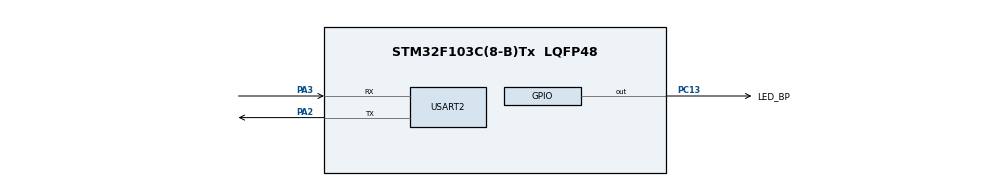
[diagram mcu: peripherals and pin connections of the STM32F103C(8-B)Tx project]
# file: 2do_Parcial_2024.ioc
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FREERTOS.Tasks01=defaultTask,24,128,StartDefaultTask,Default,NULL,Dynamic,NULL,NULL
FREERTOS.configTOTAL_HEAP_SIZE=8000
FREERTOS.configUSE_NEWLIB_REENTRANT=1
FREERTOS.configUSE_TICKLESS_IDLE=1
Mcu.Family=STM32F1
Mcu.Name=STM32F103C(8-B)Tx
Mcu.Package=LQFP48
NVIC.PriorityGroup=NVIC_PRIORITYGROUP_4
NVIC.TIM1_UP_IRQn=true\:15\:0\:false\:false\:true\:false\:false\:true\:true
NVIC.TimeBase=TIM1_UP_IRQn
NVIC.TimeBaseIP=TIM1
NVIC.USART2_IRQn=true\:5\:0\:false\:false\:true\:true\:true\:true\:true
PA13.Mode=Serial_Wire
PA13.Signal=SYS_JTMS-SWDIO
PA14.Mode=Serial_Wire
PA14.Signal=SYS_JTCK-SWCLK
PA2.Mode=Asynchronous
PA2.Signal=USART2_TX
PA3.Mode=Asynchronous
PA3.Signal=USART2_RX
PC13-TAMPER-RTC.GPIO_Label=LED_BP
PC13-TAMPER-RTC.Signal=GPIO_Output
PC14-OSC32_IN.Mode=LSE-External-Oscillator
PC14-OSC32_IN.Signal=RCC_OSC32_IN
PC15-OSC32_OUT.Mode=LSE-External-Oscillator
PC15-OSC32_OUT.Signal=RCC_OSC32_OUT
PD0-OSC_IN.Mode=HSE-External-Oscillator
PD0-OSC_IN.Signal=RCC_OSC_IN
PD1-OSC_OUT.Mode=HSE-External-Oscillator
PD1-OSC_OUT.Signal=RCC_OSC_OUT
ProjectManager.HeapSize=0x200
ProjectManager.StackSize=0x400
ProjectManager.TargetToolchain=STM32CubeIDE
RCC.APB1Freq_Value=8000000
RCC.APB2Freq_Value=8000000
USART2.VirtualMode=VM_ASYNC
VP_FREERTOS_VS_CMSIS_V2.Mode=CMSIS_V2
VP_SYS_VS_tim1.Mode=TIM1
board=custom

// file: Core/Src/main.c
/* USER CODE BEGIN Header */
/**
 ******************************************************************************
 * @file           : main.c
 * @brief          : Main program body
 ******************************************************************************
 * @attention
 *
 * Copyright (c) 2025 STMicroelectronics.
 * All rights reserved.
 *
 * This software is licensed under terms that can be found in the LICENSE file
 * in the root directory of this software component.
 * If no LICENSE file comes with this software, it is provided AS-IS.
 *
 ******************************************************************************
 */
/* USER CODE END Header */
#include "main.h"
#include "cmsis_os.h"

/* USER CODE BEGIN Includes */
#include "FreeRTOS.h"
#include "task.h"
#include "semphr.h"
#include "queue.h"
#include "string.h"
#include <stdio.h>

/* USER CODE END Includes */

/* USER CODE BEGIN PTD */

typedef struct TASK_DATA {
	uint16_t SI_PIN;
	uint16_t SF_PIN;
	uint16_t BARRERA_PIN;
	uint16_t TIPO;
	xSemaphoreHandle sem_SI;
	xSemaphoreHandle sem_SF;
}TASK_DATA_T;
/* USER CODE END PTD */

/* USER CODE BEGIN PD */
#define S1_PIN (0) /* Pin sensor entrada barrera entrada */
#define S2_PIN (1) /* Pin sensor salida barrera entrada */
#define S3_PIN (2) /* Pin sensor entrada barrera salida */
#define S4_PIN (3) /* Pin sensor salida barrera salida */
#define O1_PIN (4) /* Pin para control barrera entrada */
#define O2_PIN (5) /* Pin para control barrera salida */
#define O3_PIN (6) /* Pin semáforo verde */
#define O4_PIN (7) /* Pin semáforo rojo */

#define QUEUE_LEN (5)

#define ENTRADA 0
#define SALIDA 1
#define O5_MINUTOS 2
#define TIEMPO 60000
#define ESPERA 300000
/* USER CODE END PD */

UART_HandleTypeDef huart2;

/* Definitions for defaultTask */
osThreadId_t defaultTaskHandle;
const osThreadAttr_t defaultTask_attributes = {
		.name = "defaultTask",
		.stack_size = 128 * 4,
		.priority = (osPriority_t) osPriorityNormal,
};
/* USER CODE BEGIN PV */

uint32_t leer_nro_autos(void){return 0;}; /* Thread-safe: no */
uint32_t max_autos(void){return 0;}; /* Thread-safe: si */
void decrementar_autos(void){}; /* Thread-safe: no */
void incrementar_autos(void){}; /* Thread-safe: no */
uint32_t ingreso_permitido(void){return 0;}; /* Thread-safe: si */

/* Escribe 0 o 1 en el pin */
void gpio_write(uint16_t pin, uint32_t valor){};
/* Devuelve 0 o 1 en función del estado del pin */
uint32_t gpio_read(uint16_t pin){return 0;};
/* Envía el mensaje str de len bytes utilizando interrupciones de UART */
uint32_t uart_send(uint8_t *str, uint16_t len);
/* Prototipo del callback del handler de interrupciones de GPIO */
void HAL_GPIO_EXTI_Callback(uint16_t pin);

static TASK_DATA_T entrada, salida;

static xSemaphoreHandle mutex_colector, sem_cont;

// Para la Queue
static QueueHandle_t queue_uart;
static uint8_t dato_cola;

/* USER CODE END PV */

void SystemClock_Config(void);
static void MX_GPIO_Init(void);
static void MX_USART2_UART_Init(void);
void StartDefaultTask(void *argument);

/* USER CODE BEGIN PFP */

static void initTasksData(void)
{
	entrada.SI_PIN = S1_PIN;
	entrada.SF_PIN = S2_PIN;
	entrada.BARRERA_PIN = O1_PIN;
	entrada.sem_SI = xSemaphoreCreateBinary();
	entrada.sem_SF = xSemaphoreCreateBinary();
	entrada.TIPO = ENTRADA;

	salida.SI_PIN = S3_PIN;
	salida.SF_PIN = S4_PIN;
	salida.BARRERA_PIN = O2_PIN;
	salida.sem_SI = xSemaphoreCreateBinary();
	salida.sem_SF = xSemaphoreCreateBinary();
	salida.TIPO = SALIDA;

	gpio_write(O1_PIN,0);
	gpio_write(O2_PIN,0);
	gpio_write(O3_PIN,0);
	gpio_write(O4_PIN,0);

	mutex_colector = xSemaphoreCreateMutex();
	sem_cont = xSemaphoreCreateBinary();
}

void taskBarrera (void *a){
	TASK_DATA_T *p;
	p = (TASK_DATA_T*)a;

	uint32_t cont = 0; // Para contar el tiempo de barrera
	uint8_t item;

	while(1)
	{
		if(leer_nro_autos() < max_autos()) // Hay lugares disponibles, prendo las luces
		{
			gpio_write(O3_PIN,1);
			gpio_write(O4_PIN,0);
		}
		else if(leer_nro_autos() == max_autos() ||ingreso_permitido() == 0 )
		{
			gpio_write(O3_PIN,0);
			gpio_write(O4_PIN,1);
		}
		xSemaphoreTake(p->sem_SI,portMAX_DELAY); // Tomo semafoto del sensor de ENTRADA
		if (leer_nro_autos() == max_autos()  || ingreso_permitido() == 0) // Si esta lleno o ingreso permitido es 0 no permito la entrada de vehiculos
		{
			if(p->TIPO == SALIDA) // Es del tipo salida
			{
				gpio_write(p->BARRERA_PIN, 1); // abro la barrera de SALIDA
				while (xSemaphoreTake(p->sem_SF,0) == pdFALSE && cont < TIEMPO) // Mientras no se active S2 y el contador sea menor a 1 min
				{
					cont++; // Contador suma
					vTaskDelay(1); // Espera 1ms
				}
				// Salio del While por dos razones: por TIEMPO o se activo S2

				if (cont < TIEMPO ) // Paso el auto porque se activo el semaforo
				{
					xSemaphoreGive(sem_cont); //Reseteo contador de 5 min
					// ~~~~~~~~~~~~~~~~~~~~~~~~~~~~~~~~~
					xSemaphoreTake(mutex_colector,portMAX_DELAY);
					decrementar_autos();
					xSemaphoreGive(mutex_colector);
					// ~~~~~~~~~~~~~~~~~~~~~~~~~~~~~~~~~

					item = p->TIPO;
					xQueueSend(queue_uart, &item, 0); // Mando el mensaje a la UART
				}
			}

		}
		else // Condiciones normales
		{
			gpio_write(p->BARRERA_PIN, 1);
			while (xSemaphoreTake(p->sem_SF,0) == pdFALSE && cont < TIEMPO) // Mientras no se active S2 y el contador sea menor a 1 min
			{
				cont++; // Contador suma
				vTaskDelay(1); //Espera 1ms
			}
			// Salio del While por dos razones: por TIEMPO o se activo S2

			if (cont < TIEMPO ) // Paso el auto porque se activo el semaforo
			{

				if(p->TIPO == ENTRADA){

					xSemaphoreGive(sem_cont); //Reseteo contador de 5 min
					// ~~~~~~~~~~~~~~~~~~~~~~~~~~~~~~~~~
					xSemaphoreTake(mutex_colector,portMAX_DELAY);
					incrementar_autos();
					xSemaphoreGive(mutex_colector);
					// ~~~~~~~~~~~~~~~~~~~~~~~~~~~~~~~~~

				}else if ( p->TIPO == SALIDA)
				{
					xSemaphoreGive(sem_cont); //Reseteo contador de 5 min
					// ~~~~~~~~~~~~~~~~~~~~~~~~~~~~~~~~~
					xSemaphoreTake(mutex_colector,portMAX_DELAY);
					decrementar_autos();
					xSemaphoreGive(mutex_colector);
					// ~~~~~~~~~~~~~~~~~~~~~~~~~~~~~~~~~
				}
				item = p->TIPO;
				xQueueSend(queue_uart, &item, 0); // Mando el mensaje a la UART
			}

		}

		gpio_write(p->BARRERA_PIN, 0); // Cierro la barrera
		cont = 0; // Reseteo el contador
	}
}

void Task_uart(void *p){

	uint8_t item;
	uint8_t buff[128];

	while(1){
		xQueueReceive(queue_uart, &item, portMAX_DELAY);

		if(item == ENTRADA)
		{
			snprintf((char*)buff,128," “Barrera de ENTRADA: %d-%d\r\n”",(int)leer_nro_autos(),(int)max_autos());
		}
		if(item == SALIDA)
		{
			snprintf((char*)buff,128," “Barrera de SALIDA: %d-%d\r\n”",(int)leer_nro_autos(),(int)max_autos());
		}
		if(item == O5_MINUTOS)
		{
			snprintf((char*)buff,128," “ESTADO: %d-%d\r\n”",(int)leer_nro_autos(),(int)max_autos());
		}

		HAL_UART_Transmit(&huart2, buff, (uint16_t)strlen((char *)buff), 100);
	}

}

void Task_cont (void *a) // Esta tarea va a contar el tiempo desde que no se abrio las barreras
{
	uint8_t item;
	uint32_t cont = 0;

	while(1)
	{
		while(xSemaphoreTake(sem_cont,0) == pdFALSE && cont < ESPERA) // Espero que se termine el tiempo o Pase un auto por las BARRERAS
		{
			cont++;
			vTaskDelay(1);
		}

		if ( cont  > ESPERA ) // 5 minutos desde que no hubo autos en las barreras
		{
			item = O5_MINUTOS;
			xQueueSend(queue_uart, &item, 0);
		}

		cont = 0;
	}

}

/* USER CODE END PFP */

int main(void)
{

	/* MCU Configuration--------------------------------------------------------*/

	/* Reset of all peripherals, Initializes the Flash interface and the Systick. */
	HAL_Init();

	/* Configure the system clock */
	SystemClock_Config();

	/* Initialize all configured peripherals */
	MX_GPIO_Init();
	MX_USART2_UART_Init();
	/* USER CODE BEGIN 2 */
	initTasksData();
	/* USER CODE END 2 */

	/* Init scheduler */
	osKernelInitialize();

	/* USER CODE BEGIN RTOS_QUEUES */
	/* add queues, ... */
	queue_uart = xQueueCreate(QUEUE_LEN, sizeof(dato_cola));
	/* USER CODE END RTOS_QUEUES */

	/* Create the thread(s) */
	/* creation of defaultTask */
	defaultTaskHandle = osThreadNew(StartDefaultTask, NULL, &defaultTask_attributes);

	/* USER CODE BEGIN RTOS_THREADS */
	/* add threads, ... */
	xTaskCreate(taskBarrera, (const char *)"TaskBarrera_Entrada", configMINIMAL_STACK_SIZE, &entrada, osPriorityNormal, NULL);
	xTaskCreate(taskBarrera, (const char *)"TaskBarrera_Salida", configMINIMAL_STACK_SIZE, &salida, osPriorityNormal, NULL);
	xTaskCreate(Task_uart, (const char *)"task_uart", configMINIMAL_STACK_SIZE, NULL, osPriorityNormal, NULL);
	xTaskCreate(Task_cont, (const char *)"task_cont", configMINIMAL_STACK_SIZE, NULL, osPriorityNormal, NULL);

	/* USER CODE END RTOS_THREADS */

	/* Start scheduler */
	osKernelStart();

	/* We should never get here as control is now taken by the scheduler */

	/* Infinite loop */
	while (1)
	{

	}
}

void SystemClock_Config(void)
{
	RCC_OscInitTypeDef RCC_OscInitStruct = {0};
	RCC_ClkInitTypeDef RCC_ClkInitStruct = {0};

	/** Initializes the RCC Oscillators according to the specified parameters
	 * in the RCC_OscInitTypeDef structure.
	 */
	RCC_OscInitStruct.OscillatorType = RCC_OSCILLATORTYPE_HSI;
	RCC_OscInitStruct.HSIState = RCC_HSI_ON;
	RCC_OscInitStruct.HSICalibrationValue = RCC_HSICALIBRATION_DEFAULT;
	RCC_OscInitStruct.PLL.PLLState = RCC_PLL_NONE;
	if (HAL_RCC_OscConfig(&RCC_OscInitStruct) != HAL_OK)
	{
		Error_Handler();
	}

	/** Initializes the CPU, AHB and APB buses clocks
	 */
	RCC_ClkInitStruct.ClockType = RCC_CLOCKTYPE_HCLK|RCC_CLOCKTYPE_SYSCLK
			|RCC_CLOCKTYPE_PCLK1|RCC_CLOCKTYPE_PCLK2;
	RCC_ClkInitStruct.SYSCLKSource = RCC_SYSCLKSOURCE_HSI;
	RCC_ClkInitStruct.AHBCLKDivider = RCC_SYSCLK_DIV1;
	RCC_ClkInitStruct.APB1CLKDivider = RCC_HCLK_DIV1;
	RCC_ClkInitStruct.APB2CLKDivider = RCC_HCLK_DIV1;

	if (HAL_RCC_ClockConfig(&RCC_ClkInitStruct, FLASH_LATENCY_0) != HAL_OK)
	{
		Error_Handler();
	}
}

static void MX_USART2_UART_Init(void)
{

	huart2.Instance = USART2;
	huart2.Init.BaudRate = 115200;
	huart2.Init.WordLength = UART_WORDLENGTH_8B;
	huart2.Init.StopBits = UART_STOPBITS_1;
	huart2.Init.Parity = UART_PARITY_NONE;
	huart2.Init.Mode = UART_MODE_TX_RX;
	huart2.Init.HwFlowCtl = UART_HWCONTROL_NONE;
	huart2.Init.OverSampling = UART_OVERSAMPLING_16;
	if (HAL_UART_Init(&huart2) != HAL_OK)
	{
		Error_Handler();
	}

}

static void MX_GPIO_Init(void)
{
	GPIO_InitTypeDef GPIO_InitStruct = {0};

	/* GPIO Ports Clock Enable */
	__HAL_RCC_GPIOC_CLK_ENABLE();
	__HAL_RCC_GPIOD_CLK_ENABLE();
	__HAL_RCC_GPIOA_CLK_ENABLE();

	/*Configure GPIO pin Output Level */
	HAL_GPIO_WritePin(LED_BP_GPIO_Port, LED_BP_Pin, GPIO_PIN_RESET);

	/*Configure GPIO pin : LED_BP_Pin */
	GPIO_InitStruct.Pin = LED_BP_Pin;
	GPIO_InitStruct.Mode = GPIO_MODE_OUTPUT_PP;
	GPIO_InitStruct.Pull = GPIO_NOPULL;
	GPIO_InitStruct.Speed = GPIO_SPEED_FREQ_LOW;
	HAL_GPIO_Init(LED_BP_GPIO_Port, &GPIO_InitStruct);

}

void StartDefaultTask(void *argument)
{
	for(;;)
	{
		osDelay(1);
	}
}

void HAL_TIM_PeriodElapsedCallback(TIM_HandleTypeDef *htim)
{
	if (htim->Instance == TIM1)
	{
		HAL_IncTick();
	}
}

void Error_Handler(void)
{
	__disable_irq();
	while (1)
	{
	}
}
